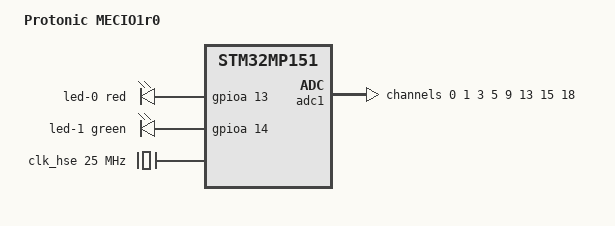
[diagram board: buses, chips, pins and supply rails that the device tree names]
// SPDX-License-Identifier: (GPL-2.0+ OR BSD-3-Clause)
/*
 * Copyright (C) Protonic Holland
 * Author: David Jander <david@protonic.nl>
 */
/dts-v1/;

#include "stm32mp151.dtsi"
#include "stm32mp15xc.dtsi"
#include "stm32mp15-pinctrl.dtsi"
#include "stm32mp15xxaa-pinctrl.dtsi"
#include "stm32mp15x-mecio1-io.dtsi"
#include <dt-bindings/gpio/gpio.h>
#include <dt-bindings/input/input.h>
#include <dt-bindings/leds/common.h>

/ {
	model = "Protonic MECIO1r0";
	compatible = "prt,mecio1r0", "st,stm32mp151";

	led {
		compatible = "gpio-leds";

		led-0 {
			color = <LED_COLOR_ID_RED>;
			function = LED_FUNCTION_DEBUG;
			gpios = <&gpioa 13 GPIO_ACTIVE_HIGH>;
		};

		led-1 {
			color = <LED_COLOR_ID_GREEN>;
			function = LED_FUNCTION_DEBUG;
			gpios = <&gpioa 14 GPIO_ACTIVE_HIGH>;
			linux,default-trigger = "heartbeat";
		};
	};
};

&adc1 {
	channel@0 {
		reg = <0>;
		st,min-sample-time-ns = <20000>;
		label = "ain_aux0";
	};

	channel@1 {
		reg = <1>;
		st,min-sample-time-ns = <20000>;
		label = "ain_aux1";
	};

	channel@3 {
		reg = <3>;
		st,min-sample-time-ns = <20000>;
		label = "hpdcm1_i2";
	};

	channel@5 {
		reg = <5>;
		st,min-sample-time-ns = <20000>;
		label = "pout1_i";
	};

	channel@9 {
		reg = <9>;
		st,min-sample-time-ns = <20000>;
		label = "pout0_i";
	};

	channel@13 {
		reg = <13>;
		st,min-sample-time-ns = <200000>;
		label = "phint1_ain";
	};

	channel@15 {
		reg = <15>;
		st,min-sample-time-ns = <20000>;
		label = "hpdcm0_i1";
	};

	channel@18 {
		reg = <18>;
		st,min-sample-time-ns = <20000>;
		label = "hpdcm0_i2";
	};
};

&clk_hse {
	clock-frequency = <25000000>;
};

&ethernet0 {
	assigned-clocks = <&rcc ETHCK_K>, <&rcc PLL3_Q>;
	assigned-clock-parents = <&rcc PLL3_Q>;
	assigned-clock-rates = <125000000>; /* Clock PLL3 to 625Mhz in tf-a. */
	st,eth-clk-sel;
};
